CM_ "IMPORT _comma.dbc";
CM_ "IMPORT _toyota_2017.dbc";
CM_ "IMPORT _toyota_nodsu_common.dbc";

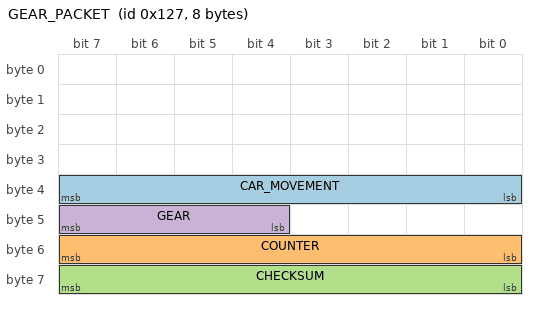
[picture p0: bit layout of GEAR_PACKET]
BO_ 295 GEAR_PACKET: 8 XXX
 SG_ CAR_MOVEMENT : 39|8@0- (1,0) [0|255] "" XXX
 SG_ COUNTER : 55|8@0+ (1,0) [0|255] "" XXX
 SG_ CHECKSUM : 63|8@0+ (1,0) [0|255] "" XXX
 SG_ GEAR : 47|4@0+ (1,0) [0|15] "" XXX

VAL_ 295 GEAR 0 "P" 1 "R" 2 "N" 3 "D" 4 "B";
